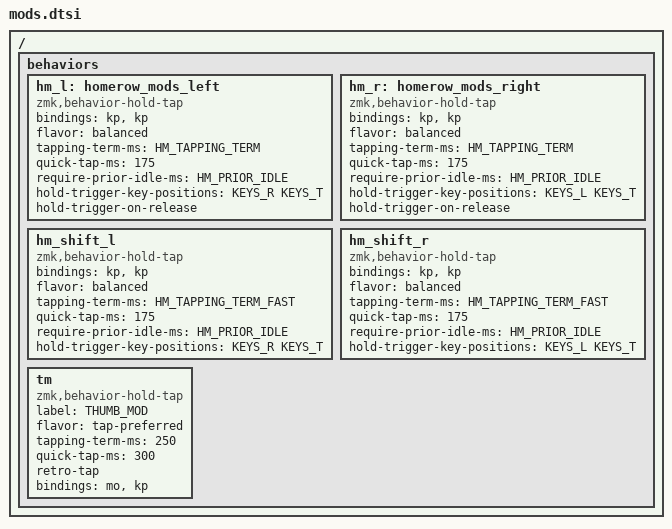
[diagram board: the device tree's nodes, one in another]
#define HM_TAPPING_TERM 300
#define HM_TAPPING_TERM_FAST 200
#define HM_PRIOR_IDLE 150

/ {
    behaviors {
        // Positional Homerow mods
        // Homerow mods that prevent accidental activations when rolling keys,
        // such as when typing `st` or `ne` on colemak-dh layouts or `as` on
        // qwerty.
        //
        // Works by only allowing a mod to activate within tapping-term if
        // it's on the opposite side of the keyboard or on the same side thumb
        // keys.

        // Further optimization using urob's timerless homerow mods method:
        // https://github.com/urob/zmk-config#timeless-homerow-mods
        hm_l: homerow_mods_left {
            compatible = "zmk,behavior-hold-tap";
            #binding-cells = <2>;
            bindings = <&kp>,  <&kp>;

            flavor = "balanced";
            tapping-term-ms = <HM_TAPPING_TERM>;
            quick-tap-ms = <175>;                // repeat on tap-into-hold
            require-prior-idle-ms = <HM_PRIOR_IDLE>;

            hold-trigger-key-positions = <KEYS_R KEYS_T>;
            hold-trigger-on-release;
        };

        hm_r: homerow_mods_right {
            compatible = "zmk,behavior-hold-tap";
            #binding-cells = <2>;
            bindings = <&kp>, <&kp>;

            flavor = "balanced";
            tapping-term-ms = <HM_TAPPING_TERM>;
            quick-tap-ms = <175>;
            require-prior-idle-ms = <HM_PRIOR_IDLE>;

            hold-trigger-key-positions = <KEYS_L KEYS_T>;
            hold-trigger-on-release;
        };


        // Positional Homerow mods for shift
        // Use faster tapping term and disable some features that may
        // cause false negatives.
        hm_shift_l: hm_shift_l {
            compatible = "zmk,behavior-hold-tap";
            #binding-cells = <2>;
            bindings = <&kp>, <&kp>;

            flavor = "balanced";
            tapping-term-ms = <HM_TAPPING_TERM_FAST>;
            quick-tap-ms = <175>;

            // replaced global-quick-tap
            require-prior-idle-ms = <HM_PRIOR_IDLE>;

            hold-trigger-key-positions = <KEYS_R KEYS_T>;
            // hold-trigger-on-release;
        };

        hm_shift_r: hm_shift_r {
            compatible = "zmk,behavior-hold-tap";
            #binding-cells = <2>;
            bindings = <&kp>, <&kp>;

            flavor = "balanced";
            tapping-term-ms = <HM_TAPPING_TERM_FAST>;
            quick-tap-ms = <175>;

            // replaced global-quick-tap
            require-prior-idle-ms = <HM_PRIOR_IDLE>;

            hold-trigger-key-positions = <KEYS_L KEYS_T>;
            // hold-trigger-on-release;
        };

        // mods for thumb keys
        tm: tm {
            compatible = "zmk,behavior-hold-tap";
            label = "THUMB_MOD";
            flavor = "tap-preferred";

            // how long a key must be pressed to trigger Hold behavior.
            tapping-term-ms = <250>;
            // press a tapped hold-tap again within quick-tap-ms milliseconds 
            // of the first press, it will always trigger the tap behavior.
            quick-tap-ms = <300>;
            // the tap behavior is triggered when releasing the hold-tap key 
            // if no other key was pressed in the meantime
            retro-tap; // don't allow slow (hold-like) taps

            #binding-cells = <2>;
            bindings = <&mo>, <&kp>;
        };

    };
};
